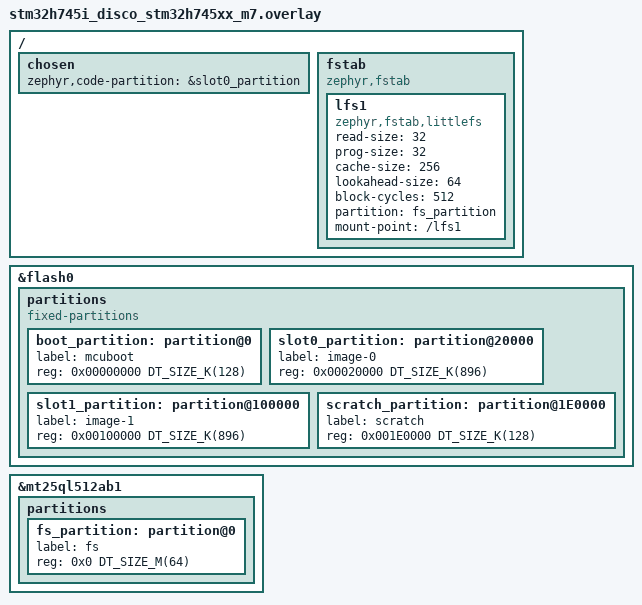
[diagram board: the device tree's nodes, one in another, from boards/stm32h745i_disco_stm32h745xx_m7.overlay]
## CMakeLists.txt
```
# SPDX-License-Identifier: Apache-2.0

cmake_minimum_required(VERSION 3.20.0)

find_package(Zephyr REQUIRED HINTS $ENV{ZEPHYR_BASE})
project(trustedge_sample C)


set(MSS_DIR  "${CMAKE_CURRENT_SOURCE_DIR}/../../..")
set(MSS_SRC_DIR "${MSS_DIR}/src")
set(TRUSTCORE_LIB_DIR "${MSS_DIR}/bin_static")

include_directories(
  ${MSS_SRC_DIR}
  ${MSS_SRC_DIR}/trustedge
)

function(builder_add_flags FLAGS_VAR)
    message("----------------")
    foreach(FLAGS_FILE IN LISTS ARGN)
        message("${FLAGS_VAR} - adding flags in ${FLAGS_FILE}")
        file(STRINGS ${FLAGS_FILE} FLAGS_TO_ADD)
        set(FLAGS_LIST "${FLAGS_LIST} ${FLAGS_TO_ADD}")
    endforeach()
    set(${FLAGS_VAR} "${${FLAGS_VAR}} ${FLAGS_LIST}" PARENT_SCOPE)
endfunction()

function(builder_finalize_flags FLAGS_VAR)
    message("----------------")
    foreach(FLAG ${${FLAGS_VAR}})
        string(STRIP "${STRIPPED_FLAGS} ${FLAG}" STRIPPED_FLAGS)
    endforeach()
    set(${FLAGS_VAR} "${STRIPPED_FLAGS}" PARENT_SCOPE)
    message("${FLAGS_VAR} = ${${FLAGS_VAR}}")
endfunction()

if ("${BOARD}" STREQUAL "native_sim")
  add_definitions("-D__ENABLE_DIGICERT_NATIVE_SIM__")
endif()

builder_add_flags(MOCANA_FLAGS "${CMAKE_CURRENT_SOURCE_DIR}/digicert_flags.txt")
builder_finalize_flags(MOCANA_FLAGS)

add_definitions("${MOCANA_FLAGS}")

if (NOT DEFINED IMAGE_NAME)
  set(IMAGE_NAME "test application")
endif()

target_compile_definitions(app PRIVATE "-DMY_IMAGE_NAME=\"${IMAGE_NAME}\"")

FILE(GLOB app_sources src/*.c)
target_sources(app PRIVATE ${app_sources})

file(GLOB EXTERNAL_LIBS "${TRUSTCORE_LIB_DIR}/*.a")

foreach(lib_path ${EXTERNAL_LIBS})
  get_filename_component(lib_name ${lib_path} NAME_WE)
  # add_and_link_library(${lib_path} ${lib_name} app)
  message(STATUS "Linking library: ${lib_name} => ${lib_path}")

  add_library(${lib_name} STATIC IMPORTED GLOBAL)
  set_target_properties(${lib_name} PROPERTIES IMPORTED_LOCATION ${lib_path})
  target_link_libraries(app PUBLIC ${lib_name})
endforeach()
```

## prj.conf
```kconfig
# Set the name of target binary
CONFIG_KERNEL_BIN_NAME="trustedge"
#CONFIG_DEBUG=y
#CONFIG_SIZE_OPTIMIZATIONS_AGGRESSIVE=y

# the number of bytes in the arena for C library malloc
CONFIG_COMMON_LIBC_MALLOC=y
#CONFIG_COMMON_LIBC_MALLOC_ARENA_SIZE=102000

CONFIG_REQUIRES_FULL_LIBC=y

# number of bytes for k_malloc
#CONFIG_HEAP_MEM_POOL_SIZE=17000

CONFIG_POSIX_API=y

# for enabling poxis threads
CONFIG_POSIX_THREADS=y # pthread
CONFIG_POSIX_TIMERS=y
CONFIG_THREAD_STACK_INFO=y
CONFIG_DYNAMIC_THREAD=y

CONFIG_DYNAMIC_THREAD_POOL_SIZE=20
#CONFIG_DYNAMIC_THREAD_STACK_SIZE=14000
CONFIG_POSIX_THREAD_KEYS_MAX=20
CONFIG_POSIX_THREAD_THREADS_MAX=20
CONFIG_MAX_PTHREAD_MUTEX_COUNT=20
CONFIG_MAX_PTHREAD_COND_COUNT=20

# Enable thread awareness for debugging tools supporting it
CONFIG_DEBUG_THREAD_INFO=y

CONFIG_LOG=y

CONFIG_SHELL=y
CONFIG_SHELL_LOG_LEVEL_INF=y

CONFIG_FILE_SYSTEM=y
CONFIG_FILE_SYSTEM_SHELL=y

CONFIG_FILE_SYSTEM_LITTLEFS=y
CONFIG_FLASH_MAP=y
CONFIG_FLASH=y

# Networking config
#CONFIG_NET_SOCKETS_LOG_LEVEL_DBG=n
CONFIG_NET_SOCKETS=y
CONFIG_NETWORKING=y
CONFIG_NET_IPV4=y
CONFIG_NET_DHCPV4=y
CONFIG_NET_IPV6=n
CONFIG_NET_IF_MAX_IPV4_COUNT=2
CONFIG_NET_TCP=y
CONFIG_NET_LOG=y
CONFIG_INIT_STACKS=y
CONFIG_NET_MAX_CONTEXTS=10

CONFIG_NET_SHELL=y

CONFIG_NET_CONFIG_SETTINGS=y
CONFIG_NET_CONFIG_NEED_IPV4=y

CONFIG_NET_MAX_CONN=10

CONFIG_ZVFS_POLL_MAX=10
CONFIG_ZVFS_OPEN_MAX=10
# Enable the DNS resolver
CONFIG_DNS_RESOLVER=y
# Enable additional buffers
CONFIG_DNS_RESOLVER_ADDITIONAL_BUF_CTR=5
# Enable additional queries
CONFIG_DNS_RESOLVER_ADDITIONAL_QUERIES=2
# Enable mDNS support
CONFIG_MDNS_RESOLVER=y
# Enable LLMNR support
CONFIG_LLMNR_RESOLVER=n

CONFIG_DNS_RESOLVER_MAX_SERVERS=2
CONFIG_DNS_SERVER_IP_ADDRESSES=y
CONFIG_DNS_NUM_CONCUR_QUERIES=5

CONFIG_DNS_SERVER1="8.8.8.8:53"
CONFIG_DNS_SERVER2="1.1.1.1:53"

CONFIG_NET_PKT_RX_COUNT=32
CONFIG_NET_PKT_TX_COUNT=32
CONFIG_NET_BUF_RX_COUNT=32
CONFIG_NET_BUF_TX_COUNT=32

CONFIG_NET_TCP_LOG_LEVEL_DBG=n

CONFIG_HWINFO=y

# Set current time from ntp server
CONFIG_SNTP=y
CONFIG_SNTP_LOG_LEVEL_DBG=y
CONFIG_NET_CONFIG_CLOCK_SNTP_INIT=y
CONFIG_NET_CONFIG_SNTP_INIT_RESYNC=y
CONFIG_NET_CONFIG_SNTP_INIT_SERVER="north-america.pool.ntp.org"

CONFIG_FRAME_POINTER=y

CONFIG_THREAD_NAME=y
#CONFIG_THREAD_ANALYZER=y
#CONFIG_THREAD_ANALYZER_AUTO=y
#CONFIG_THREAD_ANALYZER_RUN_UNLOCKED=y

CONFIG_BOOTLOADER_MCUBOOT=y
CONFIG_MCUBOOT_SIGNATURE_KEY_FILE="bootloader/mcuboot/root-rsa-2048.pem"

# CONFIG_STM32_MEMMAP depends on this. already set above
CONFIG_FLASH=y

# CONFIG_IMG_MANAGER depends on this
CONFIG_STREAM_FLASH=y

# CONFIG_MCUBOOT_IMG_MANAGER depends on this, already set above
CONFIG_FLASH_MAP=y

# required for including <zephyr/dfu/mcuboot.h>
CONFIG_IMG_MANAGER=y
CONFIG_MCUBOOT_IMG_MANAGER=y

CONFIG_IMG_BLOCK_BUF_SIZE=32

CONFIG_IMG_ENABLE_IMAGE_CHECK=y
#CONFIG_IMG_ENABLE_IMAGE_CHECK=y
CONFIG_MCUBOOT_UTIL_LOG_LEVEL_DBG=y
#CONFIG_IMG_MANAGER=y
```

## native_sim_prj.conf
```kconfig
# Set the name of target binary
CONFIG_KERNEL_BIN_NAME="trustedge"
CONFIG_DEBUG=n
CONFIG_SIZE_OPTIMIZATIONS_AGGRESSIVE=y

# the number of bytes in the arena for C library malloc
CONFIG_COMMON_LIBC_MALLOC=y
CONFIG_COMMON_LIBC_MALLOC_ARENA_SIZE=1048576

CONFIG_REQUIRES_FULL_LIBC=y

# number of bytes for k_malloc
CONFIG_HEAP_MEM_POOL_SIZE=1048576

# Networking config
CONFIG_NET_SOCKETS=y
CONFIG_NETWORKING=y
CONFIG_ENTROPY_GENERATOR=y
CONFIG_TEST_RANDOM_GENERATOR=y
CONFIG_POSIX_SEMAPHORES=y
CONFIG_POSIX_AEP_CHOICE_PSE51=y
CONFIG_POSIX_MESSAGE_PASSING=y
CONFIG_POSIX_NETWORKING=y
CONFIG_POSIX_SIGNALS=y
CONFIG_POSIX_REALTIME_SIGNALS=y
CONFIG_POSIX_API=y
CONFIG_REBOOT=y

# for enabling poxis threads
CONFIG_POSIX_THREADS=y
CONFIG_THREAD_STACK_INFO=y
CONFIG_DYNAMIC_THREAD=y

CONFIG_DYNAMIC_THREAD_POOL_SIZE=20
CONFIG_POSIX_THREAD_KEYS_MAX=20
CONFIG_POSIX_THREAD_THREADS_MAX=20
CONFIG_MAX_PTHREAD_MUTEX_COUNT=20
CONFIG_MAX_PTHREAD_COND_COUNT=20

# Enable thread awareness for debugging tools supporting it
CONFIG_DEBUG_THREAD_INFO=y

CONFIG_LOG=y

CONFIG_FLASH=y

CONFIG_SHELL=y
CONFIG_SHELL_LOG_LEVEL_INF=y

CONFIG_FILE_SYSTEM=y
CONFIG_FILE_SYSTEM_SHELL=y

CONFIG_FILE_SYSTEM_LITTLEFS=y
CONFIG_FLASH_MAP=y

# Networking config
CONFIG_NET_IPV4=y
CONFIG_NET_IF_MAX_IPV4_COUNT=2
CONFIG_NET_IF_MAX_IPV6_COUNT=2
CONFIG_NET_TCP=y
CONFIG_NET_LOG=y

CONFIG_INIT_STACKS=y
# Network address config

CONFIG_NET_CONFIG_SETTINGS=y
CONFIG_NET_CONFIG_NEED_IPV4=y
CONFIG_NET_CONFIG_MY_IPV4_ADDR="10.1.2.3"
CONFIG_ETH_NATIVE_POSIX=n
CONFIG_NET_DRIVERS=y
CONFIG_NET_SOCKETS=y
CONFIG_NET_SOCKETS_OFFLOAD=y
CONFIG_NET_NATIVE_OFFLOADED_SOCKETS=y

CONFIG_DNS_RESOLVER=y
CONFIG_DNS_SERVER_IP_ADDRESSES=y
CONFIG_DNS_SERVER1="8.8.8.8"

CONFIG_HWINFO=y

CONFIG_MAIN_STACK_SIZE=4096

# RSA_setPublicKeyData had RSA_N optimized out
CONFIG_NO_OPTIMIZATIONS=y

# Set current time from ntp server
CONFIG_SNTP=y
CONFIG_NET_CONFIG_CLOCK_SNTP_INIT=y
CONFIG_NET_CONFIG_SNTP_INIT_RESYNC=y
CONFIG_POSIX_TIMERS=y
CONFIG_NET_CONFIG_SNTP_INIT_SERVER="north-america.pool.ntp.org"

# Assign a static MAC to device
CONFIG_ETH_NATIVE_POSIX_MAC_ADDR="00:11:22:33:44:55"
CONFIG_ETH_NATIVE_POSIX=y
CONFIG_ETH_DRIVER=y
CONFIG_ETH_NATIVE_POSIX_RANDOM_MAC=n
```

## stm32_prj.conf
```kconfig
# Set the name of target binary
#CONFIG_KERNEL_BIN_NAME="trustedge"
#CONFIG_DEBUG=y
#CONFIG_SIZE_OPTIMIZATIONS_AGGRESSIVE=y

# the number of bytes in the arena for C library malloc
#CONFIG_COMMON_LIBC_MALLOC=y
CONFIG_COMMON_LIBC_MALLOC_ARENA_SIZE=110000

CONFIG_HEAP_MEM_POOL_SIZE=11000
CONFIG_DYNAMIC_THREAD_STACK_SIZE=13000
CONFIG_MAIN_STACK_SIZE=10000

#CONFIG_ZTEST_STACK_SIZE=4096
CONFIG_SYSTEM_WORKQUEUE_STACK_SIZE=4096
CONFIG_LOG_PROCESS_THREAD_STACK_SIZE=4096
CONFIG_SHELL_STACK_SIZE=4096

CONFIG_LOG_BACKEND_FS=y
CONFIG_LOG_BACKEND_FS_FILE_SIZE=1024000
CONFIG_LOG_BACKEND_FS_FILES_LIMIT=5
CONFIG_LOG_BACKEND_FS_DIR="/lfs1/log"

CONFIG_PRINTK=y
CONFIG_LOG_CMDS=y
CONFIG_INIT_STACKS=y
CONFIG_KERNEL_SHELL=y
CONFIG_THREAD_MONITOR=y
CONFIG_BOOT_BANNER=n
CONFIG_THREAD_NAME=y
CONFIG_DEVICE_SHELL=y
CONFIG_DATE_SHELL=y
CONFIG_THREAD_RUNTIME_STATS=y
CONFIG_THREAD_RUNTIME_STATS_USE_TIMING_FUNCTIONS=y
CONFIG_STATS=y
CONFIG_STATS_SHELL=y

#CONFIG_NET_CONFIG_MY_IPV4_ADDR="192.168.1.142"
#CONFIG_NET_CONFIG_PEER_IPV4_ADDR="192.168.1.124"
#CONFIG_NET_CONFIG_MY_IPV4_GW="192.168.1.1"
#CONFIG_REQUIRES_FULL_LIBC=y

# number of bytes for k_malloc

#CONFIG_POSIX_API=y

# for enabling poxis threads
#CONFIG_POSIX_THREADS=y # pthread
#CONFIG_POSIX_TIMERS=y
#CONFIG_THREAD_STACK_INFO=y
#CONFIG_DYNAMIC_THREAD=y

#CONFIG_DYNAMIC_THREAD_POOL_SIZE=20
#CONFIG_POSIX_THREAD_KEYS_MAX=20
#CONFIG_POSIX_THREAD_THREADS_MAX=20
#CONFIG_MAX_PTHREAD_MUTEX_COUNT=20
#CONFIG_MAX_PTHREAD_COND_COUNT=20

# Enable thread awareness for debugging tools supporting it
#CONFIG_DEBUG_THREAD_INFO=y

#CONFIG_LOG=y

#CONFIG_SHELL=y
#CONFIG_SHELL_LOG_LEVEL_INF=y

#CONFIG_FILE_SYSTEM=y
#CONFIG_FILE_SYSTEM_SHELL=y

#CONFIG_FILE_SYSTEM_LITTLEFS=y
#CONFIG_FLASH_MAP=y
#CONFIG_FLASH=y

# Networking config
#CONFIG_NET_SOCKETS_LOG_LEVEL_DBG=n
#CONFIG_NET_SOCKETS=y
#CONFIG_NETWORKING=y
#CONFIG_NET_IPV4=y
#CONFIG_NET_DHCPV4=y
#CONFIG_NET_IPV6=n
#CONFIG_NET_IF_MAX_IPV4_COUNT=2
#CONFIG_NET_TCP=y
#CONFIG_NET_LOG=y

#CONFIG_NET_SHELL=y

#CONFIG_NET_CONFIG_SETTINGS=y
#CONFIG_NET_CONFIG_NEED_IPV4=y

#CONFIG_NET_MAX_CONN=10

#CONFIG_ZVFS_POLL_MAX=10
#CONFIG_ZVFS_OPEN_MAX=10
# Enable the DNS resolver
#CONFIG_DNS_RESOLVER=y
# Enable additional buffers
#CONFIG_DNS_RESOLVER_ADDITIONAL_BUF_CTR=5
# Enable additional queries
#CONFIG_DNS_RESOLVER_ADDITIONAL_QUERIES=2
# Enable mDNS support
#CONFIG_MDNS_RESOLVER=y
# Enable LLMNR support
#CONFIG_LLMNR_RESOLVER=n

#CONFIG_DNS_RESOLVER_MAX_SERVERS=2
#CONFIG_DNS_SERVER_IP_ADDRESSES=y
#CONFIG_DNS_NUM_CONCUR_QUERIES=5

#CONFIG_DNS_SERVER1="8.8.8.8:53"
#CONFIG_DNS_SERVER2="1.1.1.1:53"

#CONFIG_NET_PKT_RX_COUNT=12
#CONFIG_NET_PKT_TX_COUNT=12
#CONFIG_NET_BUF_RX_COUNT=64
#CONFIG_NET_BUF_TX_COUNT=64

#CONFIG_NET_TCP_LOG_LEVEL_DBG=n

#CONFIG_HWINFO=y


# Set current time from ntp server
#CONFIG_SNTP=y
#CONFIG_SNTP_LOG_LEVEL_DBG=n
#CONFIG_NET_CONFIG_CLOCK_SNTP_INIT=y
#CONFIG_NET_CONFIG_SNTP_INIT_RESYNC=y
#CONFIG_NET_CONFIG_SNTP_INIT_SERVER="north-america.pool.ntp.org"
```

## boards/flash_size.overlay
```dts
/*
 * add file system to the build
*/

/ {
	fstab {
		compatible = "zephyr,fstab";
		lfs1: lfs1 {
			compatible = "zephyr,fstab,littlefs";
			read-size = <1>;
			prog-size = <16>;
			cache-size = <256>;
			lookahead-size = <32>;
			block-cycles = <512>;
			partition = <&fs_partition>;
			mount-point = "/lfs1";
		};
	};
};

&flash0 {
	partitions {
		compatible = "fixed-partitions";
		#address-cells = <1>;
		#size-cells = <1>;

		/* use remaining half of flash for the file system */
		fs_partition: partition@100000 {
			label = "lfs1";
			reg = <0x100000 0x300000>;
		};
	};
};
```

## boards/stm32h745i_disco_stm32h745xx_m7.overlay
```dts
/*
 * Copyright (c) 2023 S&C Electric Company <www.sandc.com>
 * Copyright (c) 2024 STMicroelectronics
 *
 * SPDX-License-Identifier: Apache-2.0
 */

/ {
	chosen {
		zephyr,code-partition = &slot0_partition;
	};

	fstab {
		compatible = "zephyr,fstab";
		lfs1: lfs1 {
			compatible = "zephyr,fstab,littlefs";
			read-size = <32>;
			prog-size = <32>;
			cache-size = <256>;
			lookahead-size = <64>;
			block-cycles = <512>;
			partition = <&fs_partition>;
			mount-point = "/lfs1";
		};
	};
};

&flash0 {
	partitions {
		compatible = "fixed-partitions";
		#address-cells = <1>;
		#size-cells = <1>;

		boot_partition: partition@0 {
			label = "mcuboot";
			reg = <0x00000000 DT_SIZE_K(128)>;
		};

		slot0_partition: partition@20000 {
			label = "image-0";
			reg = <0x00020000 DT_SIZE_K(896)>;
		};

		slot1_partition: partition@100000 {
			label = "image-1";
			reg = <0x00100000 DT_SIZE_K(896)>;
		};

		scratch_partition: partition@1E0000 {
			label = "scratch";
			reg = <0x001E0000 DT_SIZE_K(128)>;
		};
	};
};

&mt25ql512ab1 {
	partitions {
		fs_partition: partition@0 {
			label = "fs";
			reg = <0x0 DT_SIZE_M(64)>;
		};
	};
};
```

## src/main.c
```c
/*
 * Copyright (c) 2019 Jan Van Winkel <jan.van_winkel@dxplore.eu>
 *
 * SPDX-License-Identifier: Apache-2.0
 */

#include <zephyr/logging/log.h>
#define LOG_LEVEL CONFIG_LOG_DEFAULT_LEVEL
LOG_MODULE_REGISTER(app, LOG_LEVEL_DBG);

#ifndef __RTOS_ZEPHYR__
#define __RTOS_ZEPHYR__
#define __ZEPHYR_FMGMT__
#define __RTOS_LINUX__
#define __ENABLE_DIGICERT_FMGMT_FORCE_ABSOLUTE_PATH__
#endif

#include <string.h>
#include <pthread.h>
#include <stdio.h>
#include <zephyr/sys/reboot.h>
#include <zephyr/shell/shell.h>
#include <zephyr/net/socket.h>
#include <zephyr/dfu/flash_img.h>
#include <zephyr/dfu/mcuboot.h>

/* LITTLEFS */
#include <zephyr/fs/littlefs.h>
#include <zephyr/storage/flash_map.h>

/* DigiCert includes */
#include "common/moptions.h"
#include "common/mdefs.h"
#include "common/mtypes.h"
#include "common/merrors.h"
#include "common/mstdlib.h"
#include "common/mrtos.h"
#include "common/mtcp.h"
#include "common/mtcp_async.h"
#include "common/mfmgmt.h"
#include "common/common_utils.h"
#include "trustedge/utils/trustedge_utils.h"
#include "trustedge/trustedge_main.h"
#include "trustedge/agent/trustedge_agent_updatepolicy.h"

#if !defined(__ENABLE_DIGICERT_NATIVE_SIM__)
#include "dns.h"
#endif

#define STORAGE_PARTITION	fs_partition
#define STORAGE_PARTITION_ID	FIXED_PARTITION_ID(STORAGE_PARTITION)

FS_LITTLEFS_DECLARE_DEFAULT_CONFIG(lfs_data);
static struct fs_mount_t littlefs_mnt = {
    .type = FS_LITTLEFS,
    .fs_data = &lfs_data,
    .storage_dev = (void *)STORAGE_PARTITION_ID,
};

void get_partition_size(const char *mount_point)
{
    struct fs_statvfs stat;

    int ret = fs_statvfs(mount_point, &stat);
    if (ret != 0) {
        LOG_ERR("Failed to get file system stats: %d", ret);
        return;
    }

    /* Total size = block size * total number of blocks */
    uint64_t total_size = stat.f_bsize * stat.f_blocks;
    /* Available size = block size * available blocks */
    uint64_t available_size = stat.f_bsize * stat.f_bfree;

    LOG_INF("Total partition size: %llu bytes", total_size);
    LOG_INF("Available size: %llu bytes", available_size);
}

static char *mntpt_prepare(char *mntpt)
{
    char *cpy_mntpt;

    cpy_mntpt = k_malloc(strlen(mntpt) + 1);
    if (cpy_mntpt) {
        strcpy(cpy_mntpt, mntpt);
    }
    return cpy_mntpt;
}

static int cmd_mount_littlefs(char *mnt_pt) {
    if (littlefs_mnt.mnt_point != NULL) {
        return -EBUSY;
    }

    char *mntpt = mntpt_prepare(mnt_pt);

    if (!mntpt) {
        return -ENOEXEC; /* ?!? */
    }

    littlefs_mnt.mnt_point = mntpt;

    int rc = fs_mount(&littlefs_mnt);

    if (rc != 0) {
        k_free((void *)littlefs_mnt.mnt_point);
        littlefs_mnt.mnt_point = NULL;
        return -ENOEXEC;
    }

    return rc;
}

void setup_fs(char *mnt_pnt) {
    sbyte4 ret;

    ret = cmd_mount_littlefs(mnt_pnt);
    if (ret != 0)
    {
        goto exit;
    }

    get_partition_size(mnt_pnt);
exit:
    return;
}

/* shell command */
K_SEM_DEFINE(startTrustedge, 0, 1);
atomic_t cmdType = ATOMIC_INIT(0); // 0 == normal flow, 1 == reboot

static int cmd_trustedge_update(const struct shell *sh, size_t argc, char **argv)
{
	ARG_UNUSED(sh);
	ARG_UNUSED(argc);
	ARG_UNUSED(argv);
    atomic_set(&cmdType, 0);
    k_sem_give(&startTrustedge);
    return 0;
}

static int cmd_trustedge_reboot(const struct shell *sh, size_t argc, char **argv)
{
	ARG_UNUSED(sh);
	ARG_UNUSED(argc);
	ARG_UNUSED(argv);
    atomic_set(&cmdType, 1);
    k_sem_give(&startTrustedge);
    return 0;
}

static int cmd_trustedge_confirm(const struct shell *sh, size_t argc, char **argv)
{
	ARG_UNUSED(sh);
	ARG_UNUSED(argc);
	ARG_UNUSED(argv);
    atomic_set(&cmdType, 2);
    k_sem_give(&startTrustedge);
    return 0;
}

SHELL_STATIC_SUBCMD_SET_CREATE(sub_demo,
	SHELL_CMD(update, NULL, "run OTA sample.", cmd_trustedge_update),
	SHELL_CMD(reboot, NULL, "reboot device.", cmd_trustedge_reboot),
	SHELL_CMD(confirm, NULL, "confirm current image.", cmd_trustedge_confirm),
	SHELL_SUBCMD_SET_END /* Array terminated. */
);
SHELL_CMD_REGISTER(trustedge, &sub_demo, "Demo commands", NULL);
/* end shell command */

#define TRUSTEDGE_TCP_SERVER_PORT   8080
#define BUFFER_SIZE                 1024
/*********************** */
#define DOWNLOAD_FILE "payload.zip"
#define OUTPUT_DIR "tmp1"
/*********************************** */

static MSTATUS TRUSTEDGE_tcpDownloadBin(TCP_SOCKET serverSocket, ubyte2 port, sbyte *pFilename)
{
    MSTATUS status = ERR_GENERAL;
    sbyte pPayload[BUFFER_SIZE] = {0};
    sbyte pIpAddr[40] = {0};
    ubyte4 nRet = 0;
    sbyte4 bytesWritten = 0;
    sbyte4 numBytesSent = 0;
    k_timeout_t timeout = K_MSEC(2000);
    FileDescriptor pCtx = NULL;
    int totalBytes = 0;

    status = TRUSTEDGE_utilsGetHostByName("provision.digicert.com", pIpAddr);
    if (OK != status)
    {
        LOG_ERR("failed to get ip address of provision.digicert.com, status=%d\n", status);
        goto exit;
    }

    do
    {
        k_sleep(timeout);
        status = TCP_CONNECT(&serverSocket, pIpAddr, port);
    } while (OK != status);

    if (0 == DIGI_STRCMP(pFilename, "bin"))
    {
        status = FMGMT_fopen(DOWNLOAD_FILE, "wb", &pCtx);
        if (OK != status)
        {
            goto exit;
        }
    }

    status = TCP_WRITE(serverSocket, pFilename, DIGI_STRLEN(pFilename), &numBytesSent);
    if (OK != status)
    {
        goto exit;
    }

    do {

        status = TCP_READ_AVL_EX(serverSocket, pPayload, BUFFER_SIZE, &nRet, TCP_NO_TIMEOUT);
        if (ERR_TCP_READ_TIMEOUT == status)
        {
            status = OK;
            break;
        }

        if (nRet > 0)
        {
            status = FMGMT_fwrite(pPayload, 1, nRet, pCtx, &bytesWritten);
            totalBytes += bytesWritten;
            if (OK != status)
            {
                break;
            }
        }
    } while (nRet > 0);

    FMGMT_fclose(&pCtx);
    LOG_INF("firmware downloaded successfully\n");
    status = OK;

exit:

    return status;
}

void TRUSETDGE_downloadBin(void *pArg)
{
    MSTATUS status;
    TCP_SOCKET serverSocket = -1;
    sbyte *pFileRequest = (sbyte *)pArg;

    status = TRUSTEDGE_tcpDownloadBin(serverSocket, TRUSTEDGE_TCP_SERVER_PORT, pFileRequest);
    if (OK != status)
    {
        goto exit;
    }

exit:
    (void) TCP_CLOSE_SOCKET(serverSocket);
}

/* This needs to be provided by application */
static uint8_t gPartitionId = FIXED_PARTITION_ID(slot1_partition);

static MSTATUS TRUSTEDGE_SAMPLE_deviceFirmwareUpdateHandler(
    TrustEdgeArtifactAction *pAction,
    sbyte *pFile
)
{
    MSTATUS status;
    struct flash_area *fa;
    FileDescriptor pFileCtx = NULL;
    int rc = -1;
    off_t offset = 0;
    uint8_t buf[32];
    struct flash_img_context *ctx = NULL;
    sbyte *pInFilePath = NULL;

    if (NULL == pFile)
    {
        goto exit;
    }
    LOG_INF("pFile = %s\n", pFile);

    if (NULL == pAction)
    {
        goto exit;
    }

    if (NULL == pAction->pActionPath)
    {
        MSG_LOG_print(MSG_LOG_ERROR, "%s", "no file path found\n");
        goto exit;
    }

    if (TE_ACTION_INSTALL == pAction->type)
    {

        status = COMMON_UTILS_addPathComponent(
            (sbyte *) pFile, (sbyte *) pAction->pActionPath, &pInFilePath);
        if (OK != status)
        {
            goto exit;
        }

        if (FALSE == FMGMT_pathExists(pInFilePath, NULL))
        {
            status = ERR_TRUSTEDGE_AGENT_ACTION_FAILED;
            goto exit;
        }
    }

    if (FALSE == FMGMT_pathExists(pInFilePath, NULL))
    {
        LOG_ERR("file %s does not exist\n", pInFilePath);
        goto exit;
    }

    ctx = k_malloc(sizeof(struct flash_img_context));
    if (ctx == NULL) {
        goto exit;
    }

    /* partition must be erased before we write to it */
    rc = flash_area_open(gPartitionId, (const struct flash_area **) &fa);
    if(rc != 0) {
        LOG_ERR("flash_area_open:%d\n", rc);
        goto exit;
    }

    rc = flash_area_erase(fa, 0, fa->fa_size);
    if(rc != 0) {
        LOG_ERR("flash_area_erase:%d\n", rc);
        goto exit;
    }

    flash_area_close(fa);
    /* erase complete */

    rc = flash_img_init_id(ctx, gPartitionId);
    if (rc != 0) {
        LOG_ERR("flash_img_init_id:%d\n", rc);
        goto exit;
    }

    status = FMGMT_fopen(pInFilePath, "r", &pFileCtx);
    if (OK != status) {
        LOG_ERR("FMGMT_fopen:%d\n", status);
        rc = -1;
        goto exit;
    }

    status = FMGMT_fread(buf, 1, sizeof(buf), pFileCtx, &rc);
    if (OK != status) {
        LOG_ERR("pre FMGMT_fread:%d\n", status);
        rc = -1;
        goto exit;
    }

    while (rc > 0) {
        if (rc < 32) {
            for (int i = rc; i < sizeof(buf); i++) {
                buf[i] = 0xFF;
            }
            rc = 32;
        }

        rc = flash_img_buffered_write(ctx, buf, rc, false);
        if(rc) {
            LOG_ERR("flash_img_buffered_write:false:%d\n", rc);
            LOG_ERR("bytes written: %ld\n", offset);
            goto exit;
        }
        offset += rc;

        status = FMGMT_fread(buf, 1, sizeof(buf), pFileCtx, &rc);
        if (OK != status) {
            LOG_ERR("post FMGMT_fread:%d\n", status);
            rc = -1;
            goto exit;
        }
    }

    rc = flash_img_buffered_write(ctx, buf, 0, true);
    if (rc) {
        LOG_ERR("flash_img_buffered_write:true:%d\n", rc);
        goto exit;
    }

    struct mcuboot_img_header header;
    if(boot_read_bank_header(gPartitionId, &header, sizeof(header)))
    {
        LOG_ERR("Failed to read bank header\n");
        rc = -1;
        goto exit;
    }

#if 1
    LOG_INF("image header\n");
    LOG_INF("size:       %d\n", header.h.v1.image_size);
    LOG_INF("version:    %d.%d.%d.%d\n", header.h.v1.sem_ver.major,
        header.h.v1.sem_ver.minor, header.h.v1.sem_ver.revision,
        header.h.v1.sem_ver.build_num);
    LOG_INF("mcuversion: %d\n", header.mcuboot_version);
#endif

    /* TODO: enable image check and make sure image signature is good to go */

    rc = boot_request_upgrade(BOOT_UPGRADE_TEST);
    if (rc) {
        LOG_ERR("failed to request upgrade: %d\n", rc);
        goto exit;
    }

    LOG_INF("firmware update requested successfully\n");

exit:
    DIGI_FREE((void **) &pInFilePath);
    k_free(ctx);
    return rc;
}

static int validateImage(void *pArgs)
{
    MOC_UNUSED(pArgs);

    /* add checks here */
    return boot_write_img_confirmed();
}

static int get_file_size(sbyte *pFile)
{
    int ret = 0;
    sbyte4 filSize;
    struct fs_file_t fs_file;
    fs_file_t_init(&fs_file);


    ret = fs_open(&fs_file, pFile, (fs_mode_t)FS_O_READ);
    if (ret < 0)
    {
        return -1;
    }

    ret = fs_seek(&fs_file, 0, MSEEK_END);
    if (ret < 0)
    {
        return -1;
    }

    filSize = (sbyte4)fs_tell(&fs_file);
    (void) fs_close(&fs_file);

    return filSize;
}

int main()
{
    MSTATUS status;
    char *mount_point = "/lfs1";
    RTOS_THREAD clientTid = RTOS_THREAD_INVALID;
    LOG_INF("image: %s\n", MY_IMAGE_NAME);
    TrustEdgeArtifactAction action = {0};
    action.type = TE_ACTION_INSTALL;
    action.handler.type = TE_ACTION_HANDLER_SCRIPT;
    action.handler.subtype = TE_ACTION_HANDLER_SUBTYPE_NODEJS;
    action.pActionPath = "./payload/trustedge.signed.bin";

    setup_fs(mount_point);

    status = FMGMT_setMountPoint(mount_point);
    if (OK != status)
        goto exit;

    (void) FMGMT_mkdir("log", 0775);

#if !defined(__ENABLE_DIGICERT_NATIVE_SIM__)
    dnsLookupTableInit();
    TRUSTEDGE_registerDNSLookupCallback(startDnsLookup);
#endif

    while(1)
    {
        k_sem_take(&startTrustedge, K_FOREVER);
        switch(atomic_get(&cmdType))
        {
            case 0:
                (void) FMGMT_remove(DOWNLOAD_FILE, TRUE);

                status = RTOS_createThread(TRUSETDGE_downloadBin, (void *)"bin", TRUSTEDGE_MAIN, &clientTid);
                if (OK != status)
                {
                    goto exit;
                }

                pthread_join((uintptr) clientTid, NULL);

                (void) FMGMT_remove(OUTPUT_DIR, TRUE);
                (void) FMGMT_mkdir(OUTPUT_DIR, 0775);

                status = TRUSTEDGE_utilsExtractInlineZip(DOWNLOAD_FILE, 0, 0, OUTPUT_DIR);
                if (OK != status)
                {
                    LOG_ERR("TRUSTEDGE_utilsExtractInlineZip error=%d\n", status);
                    goto exit;
                }

                LOG_INF("%s has size %d\n", action.pActionPath, get_file_size(action.pActionPath));

                if (TRUSTEDGE_SAMPLE_deviceFirmwareUpdateHandler(&action, OUTPUT_DIR)) {
                    LOG_ERR("DFU failed\n");
                    goto exit;
                }
                break;
                ;;
            case 1:
                sys_reboot(SYS_REBOOT_COLD);
                break;
                ;;
            case 2:
                if (validateImage(NULL))
                {
                    LOG_ERR("Failed to validate image.\n");
                    goto exit;
                }
                LOG_INF("confirmed\n");
                break;
                ;;
            default:
                break;
        }
    }

exit:
    return 0;
}
```

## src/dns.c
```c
#include <stdint.h>
#include <zephyr/logging/log.h>
#define LOG_LEVEL CONFIG_LOG_DEFAULT_LEVEL
LOG_MODULE_DECLARE(app, LOG_LEVEL_DBG);
#include "dns.h"

DnsLookupEntry lookup_table[MAX_LOOKUPS];

void dnsLookupTableInit() {
    for(int i = 0; i < MAX_LOOKUPS; i++) {
        lookup_table[i].status = DNS_SLOT_OPEN;
        k_mutex_init(&(lookup_table[i].lock));
    }
}

#define DNS_TIMEOUT (5 * MSEC_PER_SEC)

void dns_result_cb(enum dns_resolve_status status,
		   struct dns_addrinfo *info,
		   void *user_data)
{
	char *hr_family;
	void *addr;
    int index = (int)(intptr_t)user_data;
    DnsLookupEntry *pEntry = &lookup_table[index];

	LOG_DBG("lookup table index=%d", index);
	switch (status) {
	case DNS_EAI_CANCELED:
		LOG_DBG("DNS query was canceled");
		return;
	case DNS_EAI_FAIL:
		LOG_DBG("DNS resolve failed");
		return;
	case DNS_EAI_NODATA:
		LOG_DBG("Cannot resolve address");
		return;
	case DNS_EAI_ALLDONE:
		LOG_DBG("DNS resolving finished");
        k_sem_give(&(pEntry->semaphore));
		return;
	case DNS_EAI_INPROGRESS:
		break;
	default:
		LOG_DBG("DNS resolving error (%d)", status);
		return;
	}

	if (!info) {
		return;
	}

	if (info->ai_family == AF_INET) {
		hr_family = "IPv4";
		addr = &net_sin(&info->ai_addr)->sin_addr;
	} else if (info->ai_family == AF_INET6) {
		hr_family = "IPv6";
		addr = &net_sin6(&info->ai_addr)->sin6_addr;
	} else {
		LOG_ERR("Invalid IP address family %d", info->ai_family);
		return;
	}

    k_mutex_lock(&(pEntry->lock), K_FOREVER);
    net_addr_ntop(info->ai_family, addr, pEntry->ip, IP_MAX);
    pEntry->status = DNS_RESOLVED;
    k_mutex_unlock(&(pEntry->lock));
}

int startDnsLookup(char *pName, char *pIPStr)
{
    int ret;
    int i;

    if (NULL == pName || NULL == pIPStr)
    {
        return -1;
    }

    if ((strcmp(pName, "localhost") == 0) || (strcmp(pName, "provision.digicert.com") == 0))
    {
        strcpy(pIPStr, "172.18.209.115");
        return 0;
    }

    /* is pNamed already cached? */
    for (i = 0; i < MAX_LOOKUPS; i++)
    {
        k_mutex_lock(&(lookup_table[i].lock), K_FOREVER);
        if ((lookup_table[i].status == DNS_RESOLVED) &&
            (strncmp(lookup_table[i].hostname, pName, HOSTNAME_MAX) == 0))
        {
            strncpy(pIPStr, lookup_table[i].ip, IP_MAX);
            LOG_INF("%s IPv4 address: %s", pName, pIPStr);
            k_mutex_unlock(&(lookup_table[i].lock));
            return 0;
        }
        k_mutex_unlock(&(lookup_table[i].lock));
    }

    for (i = 0; i < MAX_LOOKUPS; i++)
    {
        k_mutex_lock(&(lookup_table[i].lock), K_FOREVER);
        if (DNS_SLOT_OPEN == lookup_table[i].status)
        {
            k_sem_init(&(lookup_table[i].semaphore), 0, 1);
            strncpy(lookup_table[i].hostname, pName, HOSTNAME_MAX - 1);
            lookup_table[i].hostname[HOSTNAME_MAX - 1] = '\0';

            ret = dns_get_addr_info(pName,
                    DNS_QUERY_TYPE_A,
                    NULL,
                    dns_result_cb,
                    (void *)(intptr_t)i,
                    DNS_TIMEOUT);
            if (ret == 0) {
                lookup_table[i].status = DNS_PENDING;
            } else {
                LOG_ERR("Cannot resolve IPv4ress (%d)", ret);
                k_sem_give(&(lookup_table[i].semaphore));
            }
            k_mutex_unlock(&(lookup_table[i].lock));
            break;
        }
        k_mutex_unlock(&(lookup_table[i].lock));
    }

    if (i >= MAX_LOOKUPS) {
        LOG_ERR("DNS lookup table full");
        return -ENOMEM;
    }

    /* wait for signal that lookup is complete or timed out */
    k_sem_take(&(lookup_table[i].semaphore), K_MSEC(DNS_TIMEOUT));
    k_mutex_lock(&(lookup_table[i].lock), K_FOREVER);
    ret = -1;
    if (lookup_table[i].status == DNS_RESOLVED)
    {
        strncpy(pIPStr, lookup_table[i].ip, IP_MAX);
        LOG_INF("%s IPv4 address: %s", pName, pIPStr);
        ret = 0;
    }
    else
    {
        LOG_ERR("DNS lookup for %s IPv4 address failed", pName);
        lookup_table[i].status = DNS_SLOT_OPEN;
        lookup_table[i].hostname[0] = '\0';
        lookup_table[i].ip[0] = '\0';
    }

    k_mutex_unlock(&(lookup_table[i].lock));
    return ret;
}
```
